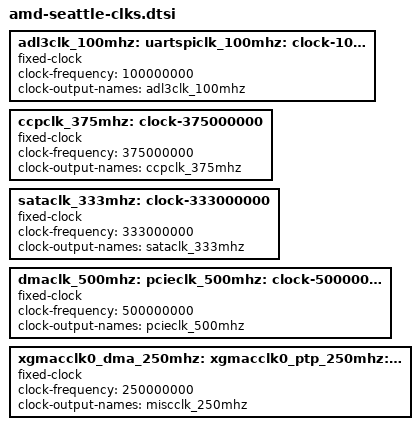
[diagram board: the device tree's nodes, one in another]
// SPDX-License-Identifier: GPL-2.0
/*
 * DTS file for AMD Seattle Clocks
 *
 * Copyright (C) 2014 Advanced Micro Devices, Inc.
 */

	adl3clk_100mhz: uartspiclk_100mhz: clock-100000000 {
		compatible = "fixed-clock";
		#clock-cells = <0>;
		clock-frequency = <100000000>;
		clock-output-names = "adl3clk_100mhz";
	};

	ccpclk_375mhz: clock-375000000 {
		compatible = "fixed-clock";
		#clock-cells = <0>;
		clock-frequency = <375000000>;
		clock-output-names = "ccpclk_375mhz";
	};

	sataclk_333mhz: clock-333000000 {
		compatible = "fixed-clock";
		#clock-cells = <0>;
		clock-frequency = <333000000>;
		clock-output-names = "sataclk_333mhz";
	};

	dmaclk_500mhz: pcieclk_500mhz: clock-500000000 {
		compatible = "fixed-clock";
		#clock-cells = <0>;
		clock-frequency = <500000000>;
		clock-output-names = "pcieclk_500mhz";
	};

	xgmacclk0_dma_250mhz: xgmacclk0_ptp_250mhz: xgmacclk1_dma_250mhz: xgmacclk1_ptp_250mhz:
	miscclk_250mhz: clock-250000000 {
		compatible = "fixed-clock";
		#clock-cells = <0>;
		clock-frequency = <250000000>;
		clock-output-names = "miscclk_250mhz";
	};

